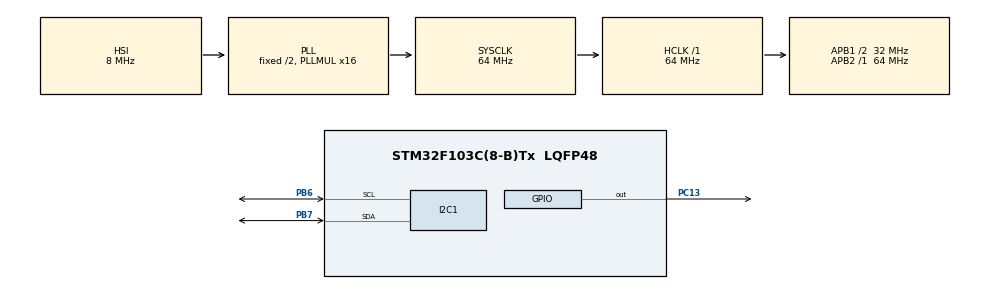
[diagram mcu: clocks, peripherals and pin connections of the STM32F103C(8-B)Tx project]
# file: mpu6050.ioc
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Mcu.Family=STM32F1
Mcu.Name=STM32F103C(8-B)Tx
Mcu.Package=LQFP48
NVIC.PriorityGroup=NVIC_PRIORITYGROUP_4
PA13.Mode=Serial_Wire
PA13.Signal=SYS_JTMS-SWDIO
PA14.Mode=Serial_Wire
PA14.Signal=SYS_JTCK-SWCLK
PB6.Mode=I2C
PB6.Signal=I2C1_SCL
PB7.Mode=I2C
PB7.Signal=I2C1_SDA
PC13-TAMPER-RTC.Signal=GPIO_Output
ProjectManager.HeapSize=0x200
ProjectManager.StackSize=0x400
ProjectManager.TargetToolchain=SW4STM32
RCC.AHBFreq_Value=64000000
RCC.APB1CLKDivider=RCC_HCLK_DIV2
RCC.APB1Freq_Value=32000000
RCC.APB1TimFreq_Value=64000000
RCC.APB2Freq_Value=64000000
RCC.APB2TimFreq_Value=64000000
RCC.HCLKFreq_Value=64000000
RCC.PLLMUL=RCC_PLL_MUL16
RCC.SYSCLKFreq_VALUE=64000000
RCC.SYSCLKSource=RCC_SYSCLKSOURCE_PLLCLK
RCC.USBFreq_Value=64000000
board=custom

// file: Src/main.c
/* USER CODE BEGIN Header */
/**
  ******************************************************************************
  * @file           : main.c
  * @brief          : Main program body
  ******************************************************************************
  * @attention
  *
  * <h2><center>&copy; Copyright (c) 2019 STMicroelectronics.
  * All rights reserved.</center></h2>
  *
  * This software component is licensed by ST under BSD 3-Clause license,
  * the "License"; You may not use this file except in compliance with the
  * License. You may obtain a copy of the License at:
  *                        opensource.org/licenses/BSD-3-Clause
  *
  ******************************************************************************
  */
/* USER CODE END Header */

#include "main.h"

/* USER CODE BEGIN Includes */
/* online library. Got from https://www.youtube.com/watch?v=-tvaeeJMW1w */
#include "TJ_MPU6050.h"
/* USER CODE END Includes */

I2C_HandleTypeDef hi2c1;

void SystemClock_Config(void);
static void MX_GPIO_Init(void);
static void MX_I2C1_Init(void);

/* USER CODE BEGIN 0 */
RawData_Def accelrawdata, gyrorawdata;
ScaledData_Def accelscaleddata, gyroscaleddata;
/* USER CODE END 0 */

int main(void)
{
  /* USER CODE BEGIN 1 */
	/* Defined at TJ_MPU6050.h, line 47.
	 * Structure to pass as argument to the function MPU_Config();*/
	MPU_ConfigTypeDef mpuconfig;
  /* USER CODE END 1 */

  /* MCU Configuration--------------------------------------------------------*/

  /* Reset of all peripherals, Initializes the Flash interface and the Systick. */
  HAL_Init();

  /* Configure the system clock */
  SystemClock_Config();

  /* Initialize all configured peripherals */
  MX_GPIO_Init();
  MX_I2C1_Init();
  /* USER CODE BEGIN 2 */
  /* Initialize MPU6050 and I2C module */
  MPU6050_Init(&hi2c1);
  /* Configure accel and gyro
   * Variables are define at TJ_MPU6050.h starting at line 45*/
  mpuconfig.Accel_Full_Scale 	= AFS_SEL_4g;
  mpuconfig.ClockSource 		= Internal_8MHz;
  mpuconfig.CONFIG_DLPF 		= DLPF_184A_188G_Hz; // digital low pass filter
  mpuconfig.Gyro_Full_Scale 	= FS_SEL_500;
  mpuconfig.Sleep_Mode_Bit		= 0;				 // 0: normal mode. 1: sleep mode.
  MPU6050_Config(&mpuconfig);

  /* USER CODE END 2 */

  /* Infinite loop */
  while (1)
  {

    /* USER CODE BEGIN 3 */
	  /* Get raw data
	   * Obs.: accelerometer must be called first because of how the library was built!*/
	  //MPU6050_Get_Accel_RawData(&accelrawdata);
	  //MPU6050_Get_Gyro_RawData(&gyrorawdata);
	  /* Get scaled data */
	  MPU6050_Get_Accel_Scale(&accelscaleddata);
	  MPU6050_Get_Gyro_Scale(&gyroscaleddata);

	  HAL_Delay(500);

  }
  /* USER CODE END 3 */
}

void SystemClock_Config(void)
{
  RCC_OscInitTypeDef RCC_OscInitStruct = {0};
  RCC_ClkInitTypeDef RCC_ClkInitStruct = {0};

  /** Initializes the CPU, AHB and APB busses clocks
  */
  RCC_OscInitStruct.OscillatorType = RCC_OSCILLATORTYPE_HSI;
  RCC_OscInitStruct.HSIState = RCC_HSI_ON;
  RCC_OscInitStruct.HSICalibrationValue = RCC_HSICALIBRATION_DEFAULT;
  RCC_OscInitStruct.PLL.PLLState = RCC_PLL_ON;
  RCC_OscInitStruct.PLL.PLLSource = RCC_PLLSOURCE_HSI_DIV2;
  RCC_OscInitStruct.PLL.PLLMUL = RCC_PLL_MUL16;
  if (HAL_RCC_OscConfig(&RCC_OscInitStruct) != HAL_OK)
  {
    Error_Handler();
  }
  /** Initializes the CPU, AHB and APB busses clocks
  */
  RCC_ClkInitStruct.ClockType = RCC_CLOCKTYPE_HCLK|RCC_CLOCKTYPE_SYSCLK
                              |RCC_CLOCKTYPE_PCLK1|RCC_CLOCKTYPE_PCLK2;
  RCC_ClkInitStruct.SYSCLKSource = RCC_SYSCLKSOURCE_PLLCLK;
  RCC_ClkInitStruct.AHBCLKDivider = RCC_SYSCLK_DIV1;
  RCC_ClkInitStruct.APB1CLKDivider = RCC_HCLK_DIV2;
  RCC_ClkInitStruct.APB2CLKDivider = RCC_HCLK_DIV1;

  if (HAL_RCC_ClockConfig(&RCC_ClkInitStruct, FLASH_LATENCY_2) != HAL_OK)
  {
    Error_Handler();
  }
}

static void MX_I2C1_Init(void)
{

  hi2c1.Instance = I2C1;
  hi2c1.Init.ClockSpeed = 100000;
  hi2c1.Init.DutyCycle = I2C_DUTYCYCLE_2;
  hi2c1.Init.OwnAddress1 = 0;
  hi2c1.Init.AddressingMode = I2C_ADDRESSINGMODE_7BIT;
  hi2c1.Init.DualAddressMode = I2C_DUALADDRESS_DISABLE;
  hi2c1.Init.OwnAddress2 = 0;
  hi2c1.Init.GeneralCallMode = I2C_GENERALCALL_DISABLE;
  hi2c1.Init.NoStretchMode = I2C_NOSTRETCH_DISABLE;
  if (HAL_I2C_Init(&hi2c1) != HAL_OK)
  {
    Error_Handler();
  }

}

static void MX_GPIO_Init(void)
{
  GPIO_InitTypeDef GPIO_InitStruct = {0};

  /* GPIO Ports Clock Enable */
  __HAL_RCC_GPIOC_CLK_ENABLE();
  __HAL_RCC_GPIOA_CLK_ENABLE();
  __HAL_RCC_GPIOB_CLK_ENABLE();

  /*Configure GPIO pin Output Level */
  HAL_GPIO_WritePin(GPIOC, GPIO_PIN_13, GPIO_PIN_RESET);

  /*Configure GPIO pin : PC13 */
  GPIO_InitStruct.Pin = GPIO_PIN_13;
  GPIO_InitStruct.Mode = GPIO_MODE_OUTPUT_PP;
  GPIO_InitStruct.Pull = GPIO_NOPULL;
  GPIO_InitStruct.Speed = GPIO_SPEED_FREQ_LOW;
  HAL_GPIO_Init(GPIOC, &GPIO_InitStruct);

}

void Error_Handler(void)
{
}

/************************ (C) COPYRIGHT STMicroelectronics *****END OF FILE****/
